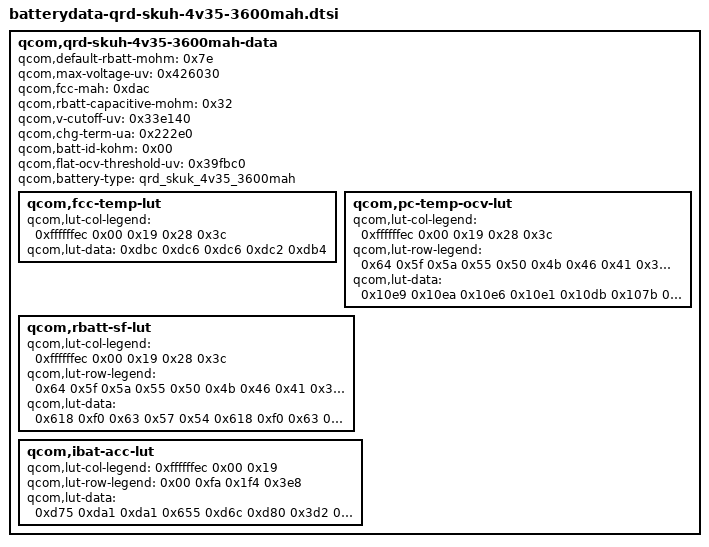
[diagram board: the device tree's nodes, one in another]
qcom,qrd-skuh-4v35-3600mah-data {
	qcom,default-rbatt-mohm = <0x7e>;
	qcom,max-voltage-uv = <0x426030>;
	qcom,fcc-mah = <0xdac>;
	qcom,rbatt-capacitive-mohm = <0x32>;
	qcom,v-cutoff-uv = <0x33e140>;
	qcom,chg-term-ua = <0x222e0>;
	qcom,batt-id-kohm = <0x00>;
	qcom,flat-ocv-threshold-uv = <0x39fbc0>;
	qcom,battery-type = "qrd_skuk_4v35_3600mah";

	qcom,fcc-temp-lut {
		qcom,lut-col-legend = <0xffffffec 0x00 0x19 0x28 0x3c>;
		qcom,lut-data = <0xdbc 0xdc6 0xdc6 0xdc2 0xdb4>;
	};

	qcom,pc-temp-ocv-lut {
		qcom,lut-col-legend = <0xffffffec 0x00 0x19 0x28 0x3c>;
		qcom,lut-row-legend = <0x64 0x5f 0x5a 0x55 0x50 0x4b 0x46 0x41 0x3c 0x37 0x32 0x2d 0x28 0x23 0x1e 0x19 0x14 0x10 0x0d 0x0b 0x0a 0x09 0x08 0x07 0x06 0x05 0x04 0x03 0x02 0x01 0x00>;
		qcom,lut-data = <0x10e9 0x10ea 0x10e6 0x10e1 0x10db 0x107b 0x109e 0x10a3 0x10a0 0x109c 0x1032 0x1066 0x106a 0x1068 0x1065 0x1008 0x1032 0x1035 0x1033 0x1030 0xfd4 0x1001 0x1001 0xfff 0xffc 0xf72 0xfd8 0xfdb 0xfd5 0xfcc 0xf46 0xf80 0xf94 0xf9b 0xfa0 0xf1c 0xf58 0xf78 0xf79 0xf78 0xf02 0xf37 0xf4c 0xf4f 0xf4e 0xef0 0xf16 0xf1e 0xf1d 0xf1c 0xee0 0xefa 0xf00 0xf00 0xf00 0xed2 0xee4 0xeea 0xeea 0xeea 0xec4 0xed2 0xed9 0xed8 0xed6 0xeb6 0xec6 0xeca 0xec9 0xec8 0xea8 0xeba 0xebc 0xeb8 0xeb4 0xe98 0xeae 0xeac 0xea3 0xe96 0xe86 0xe9e 0xe9a 0xe90 0xe84 0xe76 0xe8a 0xe86 0xe7e 0xe70 0xe66 0xe7a 0xe74 0xe6b 0xe5e 0xe58 0xe72 0xe6a 0xe63 0xe58 0xe50 0xe6f 0xe69 0xe62 0xe56 0xe46 0xe6c 0xe68 0xe60 0xe55 0xe3a 0xe68 0xe66 0xe5e 0xe52 0xe2a 0xe64 0xe62 0xe5b 0xe4e 0xe17 0xe5c 0xe5a 0xe52 0xe44 0xdfe 0xe46 0xe43 0xe36 0xe25 0xddc 0xe1e 0xe18 0xe0a 0xdfa 0xdaf 0xde8 0xde0 0xdd0 0xdc0 0xd6d 0xd9e 0xd96 0xd84 0xd74 0xd00 0xd2f 0xd26 0xd0f 0xd02 0xc1c 0xc38 0xc38 0xc1c 0xc22>;
	};

	qcom,rbatt-sf-lut {
		qcom,lut-col-legend = <0xffffffec 0x00 0x19 0x28 0x3c>;
		qcom,lut-row-legend = <0x64 0x5f 0x5a 0x55 0x50 0x4b 0x46 0x41 0x3c 0x37 0x32 0x2d 0x28 0x23 0x1e 0x19 0x14 0x10 0x0d 0x0b 0x0a 0x09 0x08 0x07 0x06 0x05 0x04 0x03 0x02 0x01 0x00>;
		qcom,lut-data = <0x618 0xf0 0x63 0x57 0x54 0x618 0xf0 0x63 0x57 0x54 0x59a 0xf3 0x64 0x57 0x54 0x55b 0xfa 0x66 0x58 0x55 0x516 0xfc 0x67 0x59 0x55 0x47c 0x119 0x6f 0x5e 0x56 0x46d 0xee 0x6c 0x5c 0x57 0x453 0xe7 0x77 0x60 0x59 0x465 0xe1 0x74 0x66 0x5c 0x478 0xdd 0x63 0x58 0x56 0x497 0xdb 0x62 0x57 0x55 0x4b6 0xde 0x62 0x57 0x55 0x4e0 0xe1 0x62 0x57 0x56 0x507 0xe6 0x64 0x59 0x57 0x531 0xf0 0x64 0x59 0x56 0x567 0xfc 0x61 0x56 0x53 0x5ab 0x10b 0x62 0x57 0x54 0x5f1 0x117 0x64 0x57 0x54 0x651 0x121 0x64 0x57 0x54 0x65e 0x123 0x63 0x56 0x54 0x61f 0x123 0x64 0x57 0x54 0x67c 0x12e 0x65 0x57 0x56 0x6ff 0x13b 0x67 0x59 0x58 0x7a8 0x14d 0x69 0x5d 0x5a 0x879 0x15d 0x6c 0x5e 0x5a 0x97e 0x16a 0x69 0x59 0x56 0xae2 0x177 0x68 0x5a 0x57 0xcce 0x19a 0x6a 0x5c 0x57 0xf98 0x1d0 0x70 0x5f 0x5a 0x16b0 0x21b 0x7d 0x6b 0x66 0x2d60 0x436 0xfb 0xd6 0xcb>;
	};

	qcom,ibat-acc-lut {
	    qcom,lut-col-legend = <0xffffffec 0x00 0x19>;
	    qcom,lut-row-legend = <0x00 0xfa 0x1f4 0x3e8>;
		qcom,lut-data = <0xd75 0xda1 0xda1 0x655 0xd6c 0xd80 0x3d2 0xd12 0xd72 0x68 0xb10 0xd50>;
	};
};
